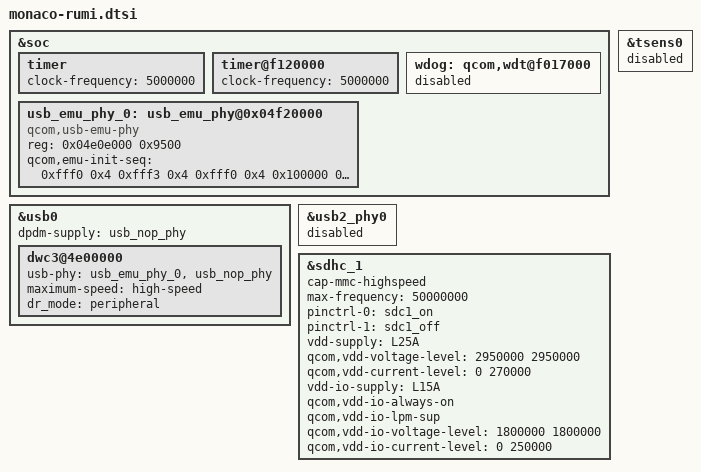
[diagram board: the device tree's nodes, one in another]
&soc {
	timer {
		clock-frequency = <5000000>;
	};

	timer@f120000 {
		clock-frequency = <5000000>;
	};

	wdog: qcom,wdt@f017000 {
		status = "disabled";
	};

	usb_emu_phy_0: usb_emu_phy@0x04f20000 {
		compatible = "qcom,usb-emu-phy";
		reg = <0x04e0e000 0x9500>;

		qcom,emu-init-seq = <0xfff0 0x4
				     0xfff3 0x4
				     0xfff0 0x4
				     0x100000 0x20
				     0x0 0x20
				     0x1e0 0x20
				     0x100000 0x3c
				     0x0 0x3c
				     0x4 0x3c
				     0x0 0x4
				     0x9 0x14>;
	};
};

&usb0 {
	dpdm-supply = <&usb_nop_phy>;
	dwc3@4e00000 {
		usb-phy = <&usb_emu_phy_0>, <&usb_nop_phy>;
		maximum-speed = "high-speed";
		dr_mode = "peripheral";
	};
};

&usb2_phy0 {
	status = "disabled";
};

&sdhc_1 {
	status = "ok";

	cap-mmc-highspeed;
	max-frequency = <50000000>;

	pinctrl-names = "default", "sleep";
	pinctrl-0 = <&sdc1_on>;
	pinctrl-1 = <&sdc1_off>;

	vdd-supply = <&L25A>;
	qcom,vdd-voltage-level = <2950000 2950000>;
	qcom,vdd-current-level = <0 270000>;

	vdd-io-supply = <&L15A>;
	qcom,vdd-io-always-on;
	qcom,vdd-io-lpm-sup;
	qcom,vdd-io-voltage-level = <1800000 1800000>;
	qcom,vdd-io-current-level = <0 250000>;
};

&tsens0 {
	status = "disabled";
};
